AUTOSAR XML (schema 00047)
# (C) 2019 HYUNDAI AUTRON Co., Ltd.
# Confidential Proprietary Information. Distribution Limited.
# Do Not Copy Without Prior Permission
package /WdgM/ClientServerInterfaces
  client server interface WdgM_GlobalSupervision: is-service=true
    5 x operation:
      GetFirstExpiredSEID: possible-error=[WdgM_GlobalSupervision/E_NOT_OK, WdgM_GlobalSupervision/E_OK]  # Returns SEID that first reached the state WDGM_LOCAL_STATUS_EXPIRED.
        arg SEID: type=WdgM_SupervisedEntityIdType, direction=OUT  # Identifier of the supervised entity that first reached the state WDGM_LOCAL_STATUS_EXPIRED.
      GetGlobalStatus: possible-error=[WdgM_GlobalSupervision/E_NOT_OK, WdgM_GlobalSupervision/E_OK]  # Returns the global supervision status of the Watchdog Manager.
        arg Status: type=WdgM_GlobalStatusType, direction=OUT  # Global supervision status of the Watchdog Manager.
      GetMode: possible-error=[WdgM_GlobalSupervision/E_NOT_OK, WdgM_GlobalSupervision/E_OK]  # Returns the current mode of the Watchdog Manager.
        arg Mode: type=WdgM_ModeType, direction=OUT  # Current mode of the Watchdog Manager.
      PerformReset  # Instructs the Watchdog Manager to cause a watchdog reset.
      SetMode: possible-error=[WdgM_GlobalSupervision/E_NOT_OK, WdgM_GlobalSupervision/E_OK]  # Sets the current mode of Watchdog Manager.
        arg Mode: type=WdgM_ModeType, direction=IN  # One of the configured Watchdog Manager modes.
    error E_NOT_OK: error-code=1  # Operation failed
    error E_OK: error-code=0  # Operation successful
  client server interface WdgM_LocalSupervision: is-service=true
    operation CheckpointReached: possible-error=[WdgM_LocalSupervision/E_NOT_OK, WdgM_LocalSupervision/E_OK]  # Indicates to the Watchdog Manager that a Checkpoint within a Supervised Entity has been reached.
    error E_NOT_OK: error-code=1  # Operation failed
    error E_OK: error-code=0  # Operation successful
  client server interface WdgM_LocalSupervisionStatus: is-service=true
    operation GetLocalStatus: possible-error=[WdgM_LocalSupervisionStatus/E_NOT_OK, WdgM_LocalSupervisionStatus/E_OK]  # Returns the supervision status of an individual Supervised Entity.
      arg Status: type=WdgM_LocalStatusType, direction=OUT  # Supervision status of the given supervised entity.
    error E_NOT_OK: error-code=1  # Operation failed
    error E_OK: error-code=0  # Operation successful
package /WdgM/DataTypeMappingSets
  data type mapping set WdgM_Mode: mode-request-type-map{implementation-data-type=uint8, mode-group=WdgM_Mode}
package /WdgM/ImplementationDataTypes
  5 x impl type, all with category=TYPE_REFERENCE:
    WdgM_CheckpointIdType: compu {0=WDGM_SE_Init_CP_Init_AS0 (SE_Init_CP_Init_AS0), 1=WDGM_SE_Init_CP_Init_ILS_0 (SE_Init_CP_Init_ILS_0), 2=WDGM_SE_Init_CP_Init_ILS_1 (SE_Init_CP_Init_ILS_1)}, implementation-data-type=uint16
    WdgM_GlobalStatusType: compu {4=WDGM_GLOBAL_STATUS_DEACTIVATED, 2=WDGM_GLOBAL_STATUS_EXPIRED, 1=WDGM_GLOBAL_STATUS_FAILED, 0=WDGM_GLOBAL_STATUS_OK, 3=WDGM_GLOBAL_STATUS_STOPPED}, implementation-data-type=uint8
    WdgM_LocalStatusType: compu {0=WDGM_LOCAL_STATUS_OK, 1=WDGM_LOCAL_STATUS_FAILED, 2=WDGM_LOCAL_STATUS_EXPIRED, 4=WDGM_LOCAL_STATUS_DEACTIVATED}, implementation-data-type=uint8
    WdgM_ModeType: compu {0=WDGM_WdgMMode0 (WdgMMode0), 1=WDGM_WdgMMode1 (WdgMMode1)}, implementation-data-type=uint8
    WdgM_SupervisedEntityIdType: compu {300=WDGM_SE_Init (SE_Init)}, implementation-data-type=uint16
package /WdgM/ModeDeclarationGroups
  mode declaration group WdgM_Mode: category=EXPLICIT_ORDER, initial-mode=SUPERVISION_OK, on-transition-value=255
    5 x mode:
      SUPERVISION_DEACTIVATED: value=4
      SUPERVISION_EXPIRED: value=2
      SUPERVISION_FAILED: value=1
      SUPERVISION_OK: value=0
      SUPERVISION_STOPPED: value=3
package /WdgM/ModeSwitchInterfaces
  mode switch interface WdgM_GlobalMode: is-service=true, service-kind=WATCH-DOG-MANAGER
    mode group currentMode: type=WdgM_Mode
  mode switch interface WdgM_LocalMode: is-service=true, service-kind=WATCH-DOG-MANAGER
    mode group currentMode: type=WdgM_Mode
package /WdgM/ServiceSwComponentTypes
  swc bsw mapping SwcBswMapping_WdgM: bsw-behavior=BswInternalBehavior_WdgM, swc-behavior=WdgMInternalBehavior
  swc implementation SwcImplementation_WdgM: swc-bsw-mapping=SwcBswMapping_WdgM, behavior=WdgMInternalBehavior
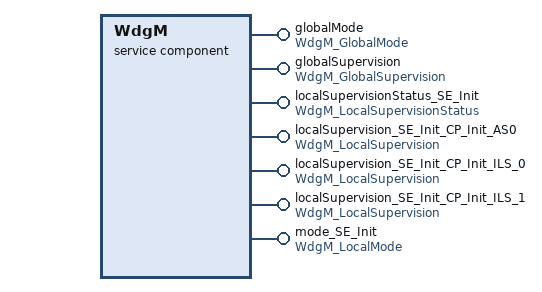
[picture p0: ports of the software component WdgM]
  service sw component type WdgM
    7 x provide port:
      globalMode: mode-switch-sender-com-spec{enhanced-mode-api=false, mode-group=WdgM_GlobalMode/currentMode, queue-length=1}, provided-interface=WdgM_GlobalMode
      globalSupervision: provided-interface=WdgM_GlobalSupervision  # This port provides the Supervision status interface of This port provides the Global Supervision interface of the WdgM. to a SWC.
        provided-com-specs:
          operation=SetMode, queue-length=1
          operation=GetMode, queue-length=1
          operation=GetGlobalStatus, queue-length=1
          operation=PerformReset, queue-length=1
          operation=GetFirstExpiredSEID, queue-length=1
      localSupervisionStatus_SE_Init: server-com-spec{operation=GetLocalStatus, queue-length=1}, provided-interface=WdgM_LocalSupervisionStatus  # This port provides the Supervision status interface of SE_Init to a SWC.
      localSupervision_SE_Init_CP_Init_AS0: server-com-spec{operation=CheckpointReached, queue-length=1}, provided-interface=WdgM_LocalSupervision  # This port provides the Supervision status interface of SE_Init_CP_Init_AS0 to a SWC.
      localSupervision_SE_Init_CP_Init_ILS_0: server-com-spec{operation=CheckpointReached, queue-length=1}, provided-interface=WdgM_LocalSupervision  # This port provides the Supervision status interface of SE_Init_CP_Init_ILS_0 to a SWC.
      localSupervision_SE_Init_CP_Init_ILS_1: server-com-spec{operation=CheckpointReached, queue-length=1}, provided-interface=WdgM_LocalSupervision  # This port provides the Supervision status interface of SE_Init_CP_Init_ILS_1 to a SWC.
      mode_SE_Init: mode-switch-sender-com-spec{enhanced-mode-api=false, mode-group=WdgM_LocalMode/currentMode, queue-length=1}, provided-interface=WdgM_LocalMode
    behavior WdgMInternalBehavior: data-type-mapping=WdgM_Mode, handle-termination-and-restart=NO-SUPPORT, included-mode-declaration-group-set=mode-declaration-group=WdgM_Mode
      9 x operation invoked event:
        OperationInvokedEvent_GetFirstExpiredSEID: start-on-event=GetFirstExpiredSEID, operation=globalSupervision.GetFirstExpiredSEID
        OperationInvokedEvent_GetGlobalStatus: start-on-event=GetGlobalStatus, operation=globalSupervision.GetGlobalStatus
        OperationInvokedEvent_GetMode: start-on-event=GetMode, operation=globalSupervision.GetMode
        OperationInvokedEvent_PerformReset: start-on-event=PerformReset, operation=globalSupervision.PerformReset
        OperationInvokedEvent_SetMode: start-on-event=SetMode, operation=globalSupervision.SetMode
        OperationInvokedEvent_localSupervision_SE_Init_CP_Init_AS0_CheckpointReached: start-on-event=CheckpointReached, operation=localSupervision_SE_Init_CP_Init_AS0.CheckpointReached
        OperationInvokedEvent_localSupervision_SE_Init_CP_Init_ILS_0_CheckpointReached: start-on-event=CheckpointReached, operation=localSupervision_SE_Init_CP_Init_ILS_0.CheckpointReached
        OperationInvokedEvent_localSupervision_SE_Init_CP_Init_ILS_1_CheckpointReached: start-on-event=CheckpointReached, operation=localSupervision_SE_Init_CP_Init_ILS_1.CheckpointReached
        OperationInvokedEvent_localSupervision_SE_Init_GetLocalStatus: start-on-event=GetLocalStatus, operation=localSupervisionStatus_SE_Init.GetLocalStatus
      port-api-options:
        {enable-take-address=false, indirect-api=false, port-defined-argument-value{value=300, value-type=WdgM_SupervisedEntityIdType}, port=localSupervisionStatus_SE_Init}
        {enable-take-address=false, indirect-api=false, port-arg-values=[{value=300, value-type=WdgM_SupervisedEntityIdType}, {value=0, value-type=WdgM_CheckpointIdType}], port=localSupervision_SE_Init_CP_Init_AS0}
        {enable-take-address=false, indirect-api=false, port-arg-values=[{value=300, value-type=WdgM_SupervisedEntityIdType}, {value=1, value-type=WdgM_CheckpointIdType}], port=localSupervision_SE_Init_CP_Init_ILS_0}
        {enable-take-address=false, indirect-api=false, port-arg-values=[{value=300, value-type=WdgM_SupervisedEntityIdType}, {value=2, value-type=WdgM_CheckpointIdType}], port=localSupervision_SE_Init_CP_Init_ILS_1}
      8 x runnable:
        CheckpointReached: arguments=[symbol=ddSEID, symbol=ddCheckpointID], can-be-invoked-concurrently=true, symbol=WdgM_CheckpointReached
        GetFirstExpiredSEID: runnable-entity-argument=symbol=pSEID, can-be-invoked-concurrently=true, symbol=WdgM_GetFirstExpiredSEID
        GetGlobalStatus: runnable-entity-argument=symbol=pStatus, can-be-invoked-concurrently=true, symbol=WdgM_GetGlobalStatus
        GetLocalStatus: arguments=[symbol=ddSEID, symbol=pStatus], can-be-invoked-concurrently=true, symbol=WdgM_GetLocalStatus
        GetMode: runnable-entity-argument=symbol=pMode, can-be-invoked-concurrently=true, symbol=WdgM_GetMode
        MainFunction: mode-access-points=[globalMode.currentMode, mode_SE_Init.currentMode], symbol=WdgM_MainFunction
          mode switch point ModeSwitchPoint_SE_Init: mode-group=mode_SE_Init.currentMode
          mode switch point ModeSwitchPoint_globalMode: mode-group=globalMode.currentMode
        PerformReset: symbol=WdgM_PerformReset
        SetMode: runnable-entity-argument=symbol=ddMode, symbol=WdgM_SetMode
